# TREMO register map
File version: 1.6.2
CPU: CM4 r0p1, little endian, MPU, FPU, 3 interrupt priority bits
Registers are 32-bit, read-write, reset 0x0 unless marked. A register's access mark holds for its fields unless they carry their own. Offsets are from the block's base; [hi:lo] are bit positions.

## RTC
Base 0x4000E000
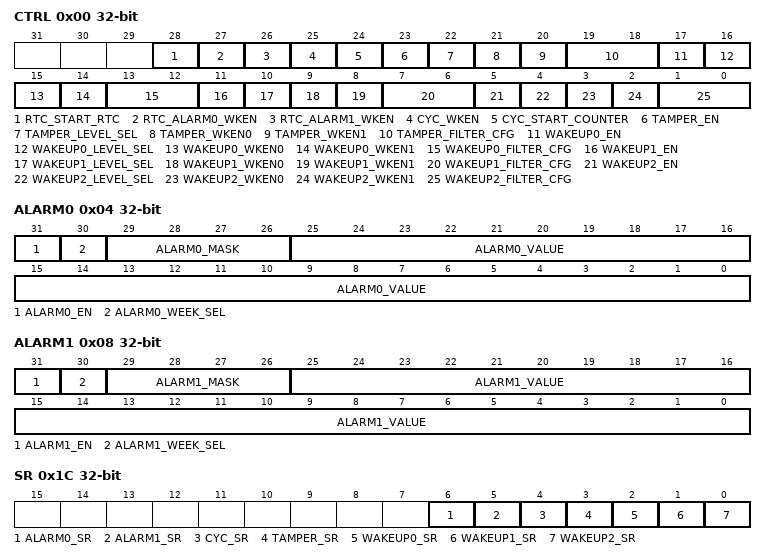
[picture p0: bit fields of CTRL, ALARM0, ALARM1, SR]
0x00 CTRL — control register
  [28] RTC_START_RTC — RTC calendar enable
  [27] RTC_ALARM0_WKEN — ALARM0_SR wake-up enable
  [26] RTC_ALARM1_WKEN — ALARM1_SR wake-up enable
  [25] CYC_WKEN — CYC_SR wake-up enable
  [24] CYC_START_COUNTER — Periodic counter enable
  [23] TAMPER_EN — Tamper enable
  [22] TAMPER_LEVEL_SEL — Tamper active level selection
  [21] TAMPER_WKEN0 — Tamper level wake-up enable
  [20] TAMPER_WKEN1 — TAMPER_SR wake-up enable
  [19:18] TAMPER_FILTER_CFG — Tamper filter control
  [17] WAKEUP0_EN — WAKEUP0 enable
  [16] WAKEUP0_LEVEL_SEL — WAKEUP0 active level selection
  [15] WAKEUP0_WKEN0 — WAKEUP0 level wake-up enable
  [14] WAKEUP0_WKEN1 — WAKEUP0_SR wake-up enable
  [13:12] WAKEUP0_FILTER_CFG — WAKEUP0 filter control
  [11] WAKEUP1_EN — WAKEUP1 enable
  [10] WAKEUP1_LEVEL_SEL — WAKEUP1 active level selection
  [9] WAKEUP1_WKEN0 — WAKEUP1 level wake-up enable
  [8] WAKEUP1_WKEN1 — WAKEUP1_SR wake-up enable
  [7:6] WAKEUP1_FILTER_CFG — WAKEUP1 filter control
  [5] WAKEUP2_EN — WAKEUP2 enable
  [4] WAKEUP2_LEVEL_SEL — WAKEUP2 active level selection
  [3] WAKEUP2_WKEN0 — WAKEUP2 level wake-up enable
  [2] WAKEUP2_WKEN1 — WAKEUP2_SR wake-up enable
  [1:0] WAKEUP2_FILTER_CFG — WAKEUP2 filter control
0x04 ALARM0
  [31] ALARM0_EN — Alarm 0 enable
  [30] ALARM0_WEEK_SEL — Date or day of week selection for Alarm 0
  [29:26] ALARM0_MASK — Alarm 0 mask configuration
  [25:0] ALARM0_VALUE — Alarm 0 value configuration
0x08 ALARM1
  [31] ALARM1_EN — Alarm 1 enable
  [30] ALARM1_WEEK_SEL — Date or day of week selection for Alarm 1
  [29:26] ALARM1_MASK — Alarm 1 mask configuration
  [25:0] ALARM1_VALUE — Alarm 1 value configuration
0x0C PPM_ADJUST (reset mask 0x7FFF) — ppm adjust value
  [15:0] PPMADJUST_VALUE
0x10 CALENDAR wo — time hour/minute/second
  [19:0] CALENDAR_VALUE — RTC calendar time values
0x14 CALENDAR_H wo reset 0x841 — time year/month/date
  [21:0] CALENDAR_H_VALUE — RTC calendar date values
0x18 CYC_MAX reset 0x8000 — cyc max value
  [31:0] CYC_MAX_VALUE — The programmed count value for the periodic counter to reach
0x1C SR — status register
  [6] ALARM0_SR — Alarm 0 flag
  [5] ALARM1_SR — Alarm 1 flag
  [4] CYC_SR — Periodic counter flag
  [3] TAMPER_SR — Tamper flag
  [2] WAKEUP0_SR — Wakeup0 flag
  [1] WAKEUP1_SR — Wakeup1 flag
  [0] WAKEUP2_SR — Wakeup2 flag
0x20 ASYN_DATA ro — asynchronization time hour/minute/second
  [19:0] SYN_DATA
0x24 ASYN_DATA_H ro — asynchronization time year/month/date
  [21:0] SYN_DATA_H
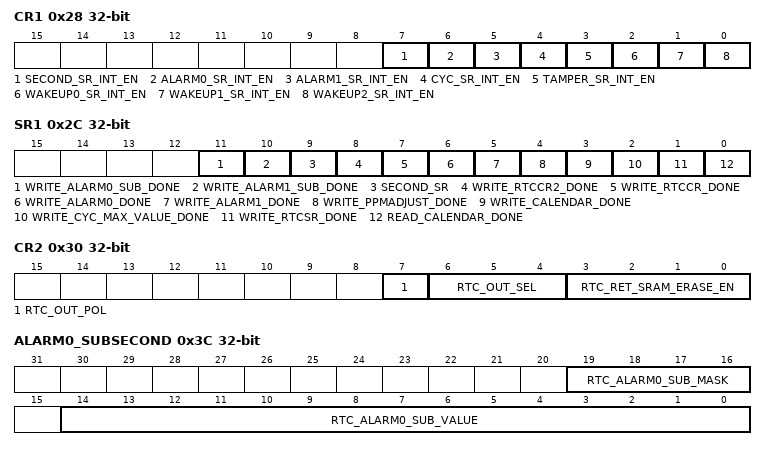
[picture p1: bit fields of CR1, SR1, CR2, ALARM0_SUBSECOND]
0x28 CR1 — control register 1
  [7] SECOND_SR_INT_EN — SECOND_SR interrupt enable
  [6] ALARM0_SR_INT_EN — ALARM0_SR interrupt enable
  [5] ALARM1_SR_INT_EN — ALARM1_SR interrupt enable
  [4] CYC_SR_INT_EN — CYC_SR (periodic counter) interrupt enable
  [3] TAMPER_SR_INT_EN — TAMPER_SR interrupt enable
  [2] WAKEUP0_SR_INT_EN — WAKEUP0_SR interrupt enable
  [1] WAKEUP1_SR_INT_EN — WAKEUP1_SR interrupt enable
  [0] WAKEUP2_SR_INT_EN — WAKEUP2_SR interrupt enable
0x2C SR1 ro — status register 1
  [11] WRITE_ALARM0_SUB_DONE — The complete flag of the write operations to register RTC_ALARM0_SUB The complete flag of the read operations to registers RTC_CALENDAR_R and RTC_CALENDAR_R_H.
  [10] WRITE_ALARM1_SUB_DONE — The complete flag of the write operations to register RTC_ALARM1_SUB The complete flag of the read operations to registers RTC_CALENDAR_R and RTC_CALENDAR_R_H.
  [9] SECOND_SR — Second signal interrupt status The complete flag of the read operations to registers RTC_CALENDAR_R and RTC_CALENDAR_R_H.
  [8] WRITE_RTCCR2_DONE — The complete flag of the write operations to register RTC_CR2 The complete flag of the read operations to registers RTC_CALENDAR_R and RTC_CALENDAR_R_H.
  [7] WRITE_RTCCR_DONE — The complete flag of the write operations to register RTC_CR The complete flag of the read operations to registers RTC_CALENDAR_R and RTC_CALENDAR_R_H.
  [6] WRITE_ALARM0_DONE — The complete flag of the write operations to register RTC_ALARM0 The complete flag of the read operations to registers RTC_CALENDAR_R and RTC_CALENDAR_R_H.
  [5] WRITE_ALARM1_DONE — The complete flag of the write operations to register RTC_ALARM1 The complete flag of the read operations to registers RTC_CALENDAR_R and RTC_CALENDAR_R_H.
  [4] WRITE_PPMADJUST_DONE — The complete flag of the write operations to register RTC_PPMADJUST The complete flag of the read operations to registers RTC_CALENDAR_R and RTC_CALENDAR_R_H.
  [3] WRITE_CALENDAR_DONE — The complete flag of the write operations to registers RTC_CALENDAR and RTC_CALENDAR_H The complete flag of the read operations to registers RTC_CALENDAR_R and RTC_CALENDAR_R_H.
  [2] WRITE_CYC_MAX_VALUE_DONE — The complete flag of the write operations to register RTC_CYC_MAX_VALUE The complete flag of the read operations to registers RTC_CALENDAR_R and RTC_CALENDAR_R_H.
  [1] WRITE_RTCSR_DONE — The complete flag of the write operation to register RTC_SR The complete flag of the read operations to registers RTC_CALENDAR_R and RTC_CALENDAR_R_H.
  [0] READ_CALENDAR_DONE — The complete flag of the read operations to registers RTC_CALENDAR_R and RTC_CALENDAR_R_H The complete flag of the read operations to registers RTC_CALENDAR_R and RTC_CALENDAR_R_H.
0x30 CR2 — control register 2
  [7] RTC_OUT_POL — RTC IO output polarity
  [6:4] RTC_OUT_SEL — RTC IO output selection
  [3:0] RTC_RET_SRAM_ERASE_EN — If enabled, the Retention SRAM is erased upon a tamper or a wakeup event
0x34 SUB_SECOND_CNT ro — subsecond counter
  [14:0] RTC_SUB_SECOND_VALUE — The subsecond count value of the RTC calendar counter
0x38 CYC_CNT ro — cyc counter
  [31:0] CYC_CNT_VALUE — Periodic counter value
0x3C ALARM0_SUBSECOND
  [19:16] RTC_ALARM0_SUB_MASK — Alarm 0 sub-second mask configuration
  [14:0] RTC_ALARM0_SUB_VALUE — Alarm 0 sub-seconds value
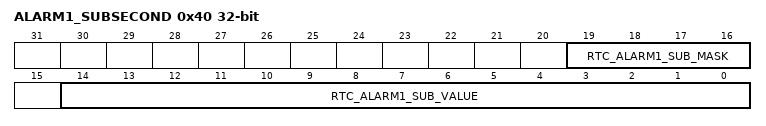
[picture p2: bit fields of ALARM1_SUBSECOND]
0x40 ALARM1_SUBSECOND
  [19:16] RTC_ALARM1_SUB_MASK — Alarm 1 sub-second mask configuration
  [14:0] RTC_ALARM1_SUB_VALUE — Alarm 1 sub-seconds value
0x44 CALENDAR_R — read time hour/minute/second
  [19:0] CALENDAR_SYNC
0x48 CALENDAR_R_H reset 0x841 — read time year/month/date
  [21:0] CALENDAR_H_SYNC
